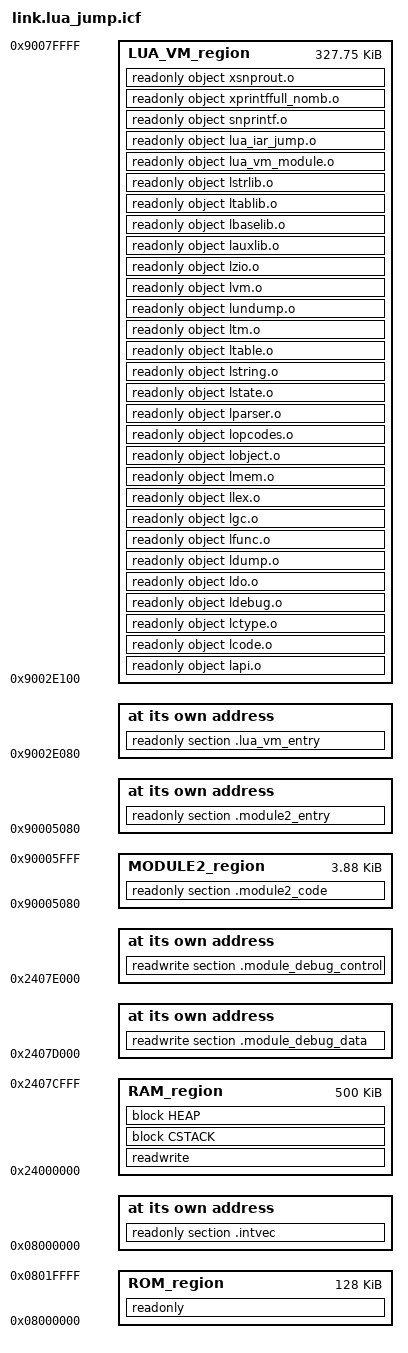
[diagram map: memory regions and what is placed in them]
/* IAR linker configuration for STM32H750 Ethernet-only RT-Thread image.
 * Minimal Ethernet/LwIP image executes directly from internal flash. */

define symbol __ICFEDIT_intvec_start__ = 0x08000000;
define symbol __ICFEDIT_region_ROM_start__ = 0x08000000;
define symbol __ICFEDIT_region_ROM_end__   = 0x0801FFFF;
define symbol __ICFEDIT_region_RAM_start__ = 0x24000000;
/*
 * Модули исполняются из W25Q128 через окно 0x90000000.
 * 0x2407D000..0x2407EFFF зарезервировано под загрузку W25Q128 через J-Link.
 * Верхняя страница AXI SRAM 0x2407F000 зарезервирована под API модулей.
 */
define symbol __ICFEDIT_region_RAM_end__   = 0x2407CFFF;

define memory mem with size = 4G;
define region ROM_region = mem:[from __ICFEDIT_region_ROM_start__
                                to __ICFEDIT_region_ROM_end__];
define region RAM_region = mem:[from __ICFEDIT_region_RAM_start__
                                to __ICFEDIT_region_RAM_end__];
define region MODULE2_region = mem:[from 0x90005080 to 0x90005FFF];
define region LUA_VM_region = mem:[from 0x9002E100 to 0x9007FFFF];

define block CSTACK with alignment = 8, size = 0x1000 { };
define block HEAP   with alignment = 8, size = 0x1000 { };

initialize by copy { readwrite };
do not initialize { section .noinit };

place at address mem:__ICFEDIT_intvec_start__ { readonly section .intvec };
place at address mem:0x2407D000 { readwrite section .module_debug_data };
place at address mem:0x2407E000 { readwrite section .module_debug_control };
place at address mem:0x90005080 { readonly section .module2_entry };
place in MODULE2_region { readonly section .module2_code };
place at address mem:0x9002E080 { readonly section .lua_vm_entry };
place in LUA_VM_region {
    readonly object lapi.o,
    readonly object lcode.o,
    readonly object lctype.o,
    readonly object ldebug.o,
    readonly object ldo.o,
    readonly object ldump.o,
    readonly object lfunc.o,
    readonly object lgc.o,
    readonly object llex.o,
    readonly object lmem.o,
    readonly object lobject.o,
    readonly object lopcodes.o,
    readonly object lparser.o,
    readonly object lstate.o,
    readonly object lstring.o,
    readonly object ltable.o,
    readonly object ltm.o,
    readonly object lundump.o,
    readonly object lvm.o,
    readonly object lzio.o,
    readonly object lauxlib.o,
    readonly object lbaselib.o,
    readonly object ltablib.o,
    readonly object lstrlib.o,
    readonly object lua_vm_module.o,
    readonly object lua_iar_jump.o,
    readonly object snprintf.o,
    readonly object xprintffull_nomb.o,
    readonly object xsnprout.o
};
place in ROM_region { readonly };
place in RAM_region { readwrite, block CSTACK, block HEAP };
